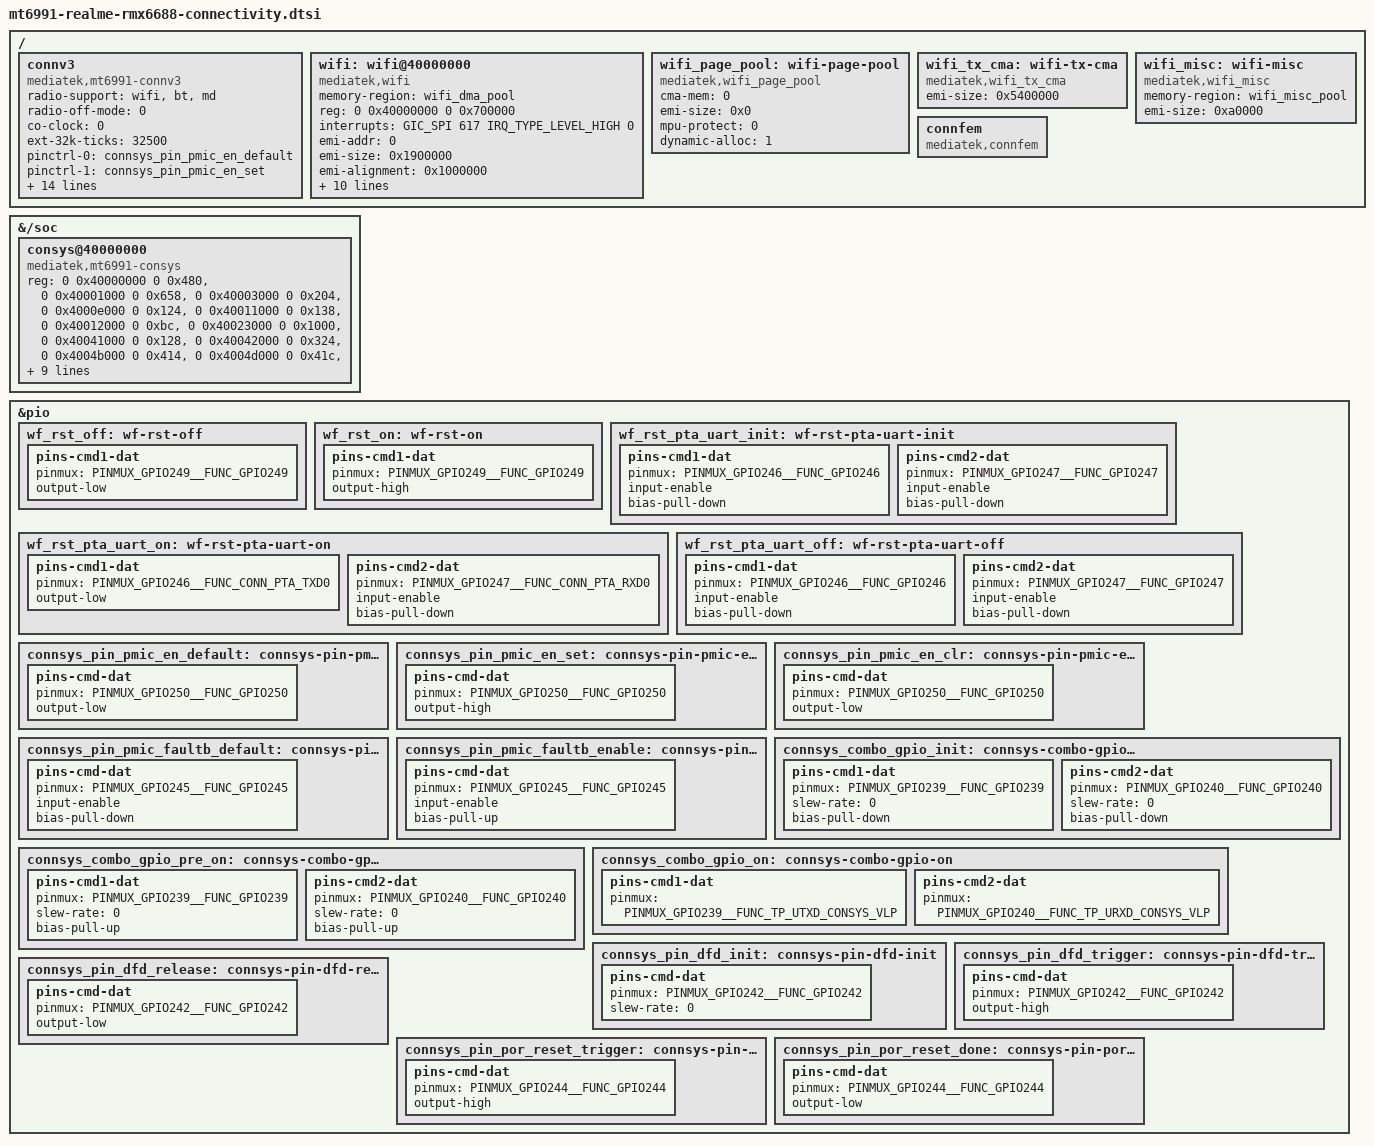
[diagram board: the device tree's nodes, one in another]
// SPDX-License-Identifier: (GPL-2.0 OR BSD-2-Clause)
/*
 * realme GT7 (RMX6688) connectivity (MT6653 / connv3) nodes.
 *
 * Adapted from the vendor MT6991 device tree.  Unsupported vendor phandles
 * (scpsys power domain, dvfsrc interconnect/OPP) are intentionally omitted;
 * the conninfra/connv3 drivers manage CONN power through the PMIC/registers.
 */

/ {
	connv3 {
		compatible = "mediatek,mt6991-connv3";
		radio-support = "wifi", "bt", "md";
		radio-off-mode = <0>;
		co-clock = <0>;
		ext-32k-ticks = <32500>;
		pinctrl-names = "connsys-pin-pmic-en-default",
			"connsys-pin-pmic-en-set",
			"connsys-pin-pmic-en-clr",
			"connsys-pin-pmic-faultb-default",
			"connsys-pin-pmic-faultb-enable",
			"connsys-combo-gpio-init",
			"connsys-combo-gpio-pre-on",
			"connsys-combo-gpio-on",
			"connsys-pin-dfd-init",
			"connsys-pin-dfd-trigger",
			"connsys-pin-dfd-release",
			"connsys-pin-por-reset-trigger",
			"connsys-pin-por-reset-done";
		pinctrl-0 = <&connsys_pin_pmic_en_default>;
		pinctrl-1 = <&connsys_pin_pmic_en_set>;
		pinctrl-2 = <&connsys_pin_pmic_en_clr>;
		pinctrl-3 = <&connsys_pin_pmic_faultb_default>;
		pinctrl-4 = <&connsys_pin_pmic_faultb_enable>;
		pinctrl-5 = <&connsys_combo_gpio_init>;
		pinctrl-6 = <&connsys_combo_gpio_pre_on>;
		pinctrl-7 = <&connsys_combo_gpio_on>;
		pinctrl-8 = <&connsys_pin_dfd_init>;
		pinctrl-9 = <&connsys_pin_dfd_trigger>;
		pinctrl-10 = <&connsys_pin_dfd_release>;
		pinctrl-11 = <&connsys_pin_por_reset_trigger>;
		pinctrl-12 = <&connsys_pin_por_reset_done>;
		interrupt-parent = <&pio>;
		mt6376-gpio = <&pio 245 0>,
				<&pio 250 0>;
		interrupts = <245 IRQ_TYPE_EDGE_FALLING>;
	};

	wifi: wifi@40000000 {
		compatible = "mediatek,wifi";
		memory-region = <&wifi_dma_pool>;
		reg = <0 0x40000000 0 0x700000>;
		interrupts = <GIC_SPI 617 IRQ_TYPE_LEVEL_HIGH 0>;
		emi-addr = <0>;
		emi-size = <0x1900000>;
		emi-alignment = <0x1000000>;
		emi-max-addr = <0xc0000000>;
		flavor-bin = "2g2a";
		pinctrl-names = "wf_rst_off",
				"wf_rst_on",
				"wf_rst_pta_uart_init",
				"wf_rst_pta_uart_on",
				"wf_rst_pta_uart_off";
		pinctrl-0 = <&wf_rst_off>;
		pinctrl-1 = <&wf_rst_on>;
		pinctrl-2 = <&wf_rst_pta_uart_init>;
		pinctrl-3 = <&wf_rst_pta_uart_on>;
		pinctrl-4 = <&wf_rst_pta_uart_off>;
		conninfra-emi-addr = <0 0xed000000>;
		conninfra-emi-size = <0xc00000>;
		ppb-emi-offset = <0x01605800>;
		#thermal-sensor-cells = <1>;
	};

	wifi_page_pool: wifi-page-pool {
		compatible = "mediatek,wifi_page_pool";
		cma-mem = <0>;
		emi-size = <0x0>;
		mpu-protect = <0>;
		dynamic-alloc = <1>;
	};

	wifi_tx_cma: wifi-tx-cma {
		compatible = "mediatek,wifi_tx_cma";
		emi-size = <0x5400000>;
	};

	wifi_misc: wifi-misc {
		compatible = "mediatek,wifi_misc";
		memory-region = <&wifi_misc_pool>;
		emi-size = <0xa0000>;
	};

	connfem: connfem {
		compatible = "mediatek,connfem";
	};
};

&{/soc} {
	consys@40000000 {
		compatible = "mediatek,mt6991-consys";
		reg = <0 0x40000000 0 0x480>,
			<0 0x40001000 0 0x658>,
			<0 0x40003000 0 0x204>,
			<0 0x4000e000 0 0x124>,
			<0 0x40011000 0 0x138>,
			<0 0x40012000 0 0xbc>,
			<0 0x40023000 0 0x1000>,
			<0 0x40041000 0 0x128>,
			<0 0x40042000 0 0x324>,
			<0 0x4004b000 0 0x414>,
			<0 0x4004d000 0 0x41c>,
			<0 0x40050000 0 0x2000>,
			<0 0x40060000 0 0xbf8>,
			<0 0x40070000 0 0x7004>,
			<0 0x1002c000 0 0xb04>,
			<0 0x1c004000 0 0x1000>,
			<0 0x1c011000 0 0x918>;
		radio-support = "gps", "mawd";
		interrupts = <GIC_SPI 806 IRQ_TYPE_LEVEL_HIGH 0>;
		emi-addr = <0 0xedc00000>;
		emi-size = <0x2fa0000>;
		gps-emi-offset = <0x4f0000>;
		gps-emi-size = <0x140000>;
	};
};

&pio {
	wf_rst_off: wf-rst-off {
		pins-cmd1-dat {
			pinmux = <PINMUX_GPIO249__FUNC_GPIO249>;
			output-low;
		};
	};
	wf_rst_on: wf-rst-on {
		pins-cmd1-dat {
			pinmux = <PINMUX_GPIO249__FUNC_GPIO249>;
			output-high;
		};
	};
	wf_rst_pta_uart_init: wf-rst-pta-uart-init {
		pins-cmd1-dat {
			pinmux = <PINMUX_GPIO246__FUNC_GPIO246>;
			input-enable;
			bias-pull-down;
		};
		pins-cmd2-dat {
			pinmux = <PINMUX_GPIO247__FUNC_GPIO247>;
			input-enable;
			bias-pull-down;
		};
	};
	wf_rst_pta_uart_on: wf-rst-pta-uart-on {
		pins-cmd1-dat {
			pinmux = <PINMUX_GPIO246__FUNC_CONN_PTA_TXD0>;
			output-low;
		};
		pins-cmd2-dat {
			pinmux = <PINMUX_GPIO247__FUNC_CONN_PTA_RXD0>;
			input-enable;
			bias-pull-down;
		};
	};
	wf_rst_pta_uart_off: wf-rst-pta-uart-off {
		pins-cmd1-dat {
			pinmux = <PINMUX_GPIO246__FUNC_GPIO246>;
			input-enable;
			bias-pull-down;
		};
		pins-cmd2-dat {
			pinmux = <PINMUX_GPIO247__FUNC_GPIO247>;
			input-enable;
			bias-pull-down;
		};
	};
	connsys_pin_pmic_en_default: connsys-pin-pmic-en-default {
		pins-cmd-dat {
			pinmux = <PINMUX_GPIO250__FUNC_GPIO250>;
			output-low;
		};
	};
	connsys_pin_pmic_en_set: connsys-pin-pmic-en-set {
		pins-cmd-dat {
			pinmux = <PINMUX_GPIO250__FUNC_GPIO250>;
			output-high;
		};
	};
	connsys_pin_pmic_en_clr: connsys-pin-pmic-en-clr {
		pins-cmd-dat {
			pinmux = <PINMUX_GPIO250__FUNC_GPIO250>;
			output-low;
		};
	};
	connsys_pin_pmic_faultb_default: connsys-pin-pmic-faultb-default {
		pins-cmd-dat {
			pinmux = <PINMUX_GPIO245__FUNC_GPIO245>;
			input-enable;
			bias-pull-down;
		};
	};
	connsys_pin_pmic_faultb_enable: connsys-pin-pmic-faultb-enable {
		pins-cmd-dat {
			pinmux = <PINMUX_GPIO245__FUNC_GPIO245>;
			input-enable;
			bias-pull-up;
		};
	};
	connsys_combo_gpio_init: connsys-combo-gpio-init {
		pins-cmd1-dat {
			pinmux = <PINMUX_GPIO239__FUNC_GPIO239>;
			slew-rate = <0>;
			bias-pull-down;
		};
		pins-cmd2-dat {
			pinmux = <PINMUX_GPIO240__FUNC_GPIO240>;
			slew-rate = <0>;
			bias-pull-down;
		};
	};
	connsys_combo_gpio_pre_on: connsys-combo-gpio-pre-on {
		pins-cmd1-dat {
			pinmux = <PINMUX_GPIO239__FUNC_GPIO239>;
			slew-rate = <0>;
			bias-pull-up;
		};
		pins-cmd2-dat {
			pinmux = <PINMUX_GPIO240__FUNC_GPIO240>;
			slew-rate = <0>;
			bias-pull-up;
		};
	};
	connsys_combo_gpio_on: connsys-combo-gpio-on {
		pins-cmd1-dat {
			pinmux = <PINMUX_GPIO239__FUNC_TP_UTXD_CONSYS_VLP>;
		};
		pins-cmd2-dat {
			pinmux = <PINMUX_GPIO240__FUNC_TP_URXD_CONSYS_VLP>;
		};
	};
	connsys_pin_dfd_init: connsys-pin-dfd-init {
		pins-cmd-dat {
			pinmux = <PINMUX_GPIO242__FUNC_GPIO242>;
			slew-rate = <0>;
		};
	};
	connsys_pin_dfd_trigger: connsys-pin-dfd-trigger {
		pins-cmd-dat {
			pinmux = <PINMUX_GPIO242__FUNC_GPIO242>;
			output-high;
		};
	};
	connsys_pin_dfd_release: connsys-pin-dfd-release {
		pins-cmd-dat {
			pinmux = <PINMUX_GPIO242__FUNC_GPIO242>;
			output-low;
		};
	};
	connsys_pin_por_reset_trigger: connsys-pin-por-reset-trigger {
		pins-cmd-dat {
			pinmux = <PINMUX_GPIO244__FUNC_GPIO244>;
			output-high;
		};
	};
	connsys_pin_por_reset_done: connsys-pin-por-reset-done {
		pins-cmd-dat {
			pinmux = <PINMUX_GPIO244__FUNC_GPIO244>;
			output-low;
		};
	};
};
